# leon2_model: IP-XACT component
VLNV IcronTechnologies:IcronTechnologies:leon2_model:1.0

## Parameters
addr_width = 8
bus_width = 32

## Bus interfaces (logical=physical port)
default_map: slave AGNISYS:AGNISYS:APB:1.0, memory map leon2map
  pclk=pclk, presetn=presetn, psel=psel, penable=penable, pwrite=pwrite, pprot=pprot, pstrb=pstrb, pwdata=pwdata, paddr=paddr, pready=pready, prdata=prdata, pslverr=pslverr

## Ports
in pclk
in presetn
in psel
in penable
in pwrite
in pprot[2:0]
in pstrb[(bus_width div 8 )-1:0]
in pwdata[bus_width -1:0]
in paddr[addr_width -1:0]
out pready
out prdata[bus_width -1:0]
out pslverr
in leon2_regsleon_config_dsu_in
in leon2_regsleon_config_dsu_in_enb
in leon2_regsleon_config_sdram_ctrl_in
in leon2_regsleon_config_sdram_ctrl_in_enb
in leon2_regsleon_config_num_wp_in[2:0]
in leon2_regsleon_config_num_wp_in_enb
in leon2_regsleon_config_mac_in
in leon2_regsleon_config_mac_in_enb
in leon2_regsleon_config_nwindows_in[4:0]
in leon2_regsleon_config_nwindows_in_enb
in leon2_regsleon_config_icsz_in[2:0]
in leon2_regsleon_config_icsz_in_enb
in leon2_regsleon_config_ilsz_in[1:0]
in leon2_regsleon_config_ilsz_in_enb
in leon2_regsleon_config_dcsz_in[2:0]
in leon2_regsleon_config_dcsz_in_enb
in leon2_regsleon_config_dlsz_in[1:0]
in leon2_regsleon_config_dlsz_in_enb
in leon2_regsleon_config_div_in
in leon2_regsleon_config_div_in_enb
in leon2_regsleon_config_mul_in
in leon2_regsleon_config_mul_in_enb
in leon2_regsleon_config_ahb_stat_in
in leon2_regsleon_config_ahb_stat_in_enb
in leon2_regsleon_config_fpu_in[1:0]
in leon2_regsleon_config_fpu_in_enb
in leon2_regsleon_config_pci_core_in[1:0]
in leon2_regsleon_config_pci_core_in_enb
in leon2_regsleon_config_write_prot_in[1:0]
in leon2_regsleon_config_write_prot_in_enb
out leon2_regsmem_ctrl_mcfg{n}_enb (n=1..3)
out leon2_regsmem_ctrl_mcfg1_io_bus_width_r[31:0]
out leon2_regsmem_ctrl_mcfg1_bus_rdy_en_r
out leon2_regsmem_ctrl_mcfg1_bus_err_en_r
out leon2_regsmem_ctrl_mcfg1_io_ws_r[3:0]
out leon2_regsmem_ctrl_mcfg1_io_en_r
out leon2_regsmem_ctrl_mcfg1_prom_wr_en_r
out leon2_regsmem_ctrl_mcfg1_prom_width_r[1:0]
out leon2_regsmem_ctrl_mcfg1_prom_wr_ws_r[3:0]
out leon2_regsmem_ctrl_mcfg1_prom_rd_ws_r[3:0]
out leon2_regsmem_ctrl_mcfg2_sdram_refresh_r
out leon2_regsmem_ctrl_mcfg2_sdram_trp_r
out leon2_regsmem_ctrl_mcfg2_sdram_trfc_r[2:0]
out leon2_regsmem_ctrl_mcfg2_sdram_cas_dly_r
out leon2_regsmem_ctrl_mcfg2_sdram_bank_size_r[2:0]
out leon2_regsmem_ctrl_mcfg2_sdram_col_size_r[1:0]
out leon2_regsmem_ctrl_mcfg2_sdram_cmd_r[1:0]
out leon2_regsmem_ctrl_mcfg2_sdram_64_r
out leon2_regsmem_ctrl_mcfg2_sdram_enable_r
out leon2_regsmem_ctrl_mcfg2_sram_disable_r
out leon2_regsmem_ctrl_mcfg2_ram_bank_size_r[3:0]
out leon2_regsmem_ctrl_mcfg2_bus_rdy_en_r
out leon2_regsmem_ctrl_mcfg2_rmw_r
out leon2_regsmem_ctrl_mcfg2_ram_width_r[1:0]
out leon2_regsmem_ctrl_mcfg2_ram_wr_ws_r[1:0]
out leon2_regsmem_ctrl_mcfg2_ram_rd_ws_r[1:0]
out leon2_regsmem_ctrl_mcfg3_sdram_refresh_val_r[14:0]
out leon2_regscache_controller_cache_control_enb
out leon2_regscache_controller_cache_control_ds_r
out leon2_regscache_controller_cache_control_fd_r
out leon2_regscache_controller_cache_control_fi_r
out leon2_regscache_controller_cache_control_ib_r
out leon2_regscache_controller_cache_control_dcf_r
out leon2_regscache_controller_cache_control_icf_r
out leon2_regscache_controller_cache_control_dcs_r[1:0]
out leon2_regscache_controller_cache_control_ics_r[1:0]
out leon2_regscache_controller_power_down_enb
out leon2_regscache_controller_power_down_pd_r[31:0]
out leon2_regstimers_timer1_counter_enb
out leon2_regstimers_timer1_counter_counter_r[23:0]
out leon2_regstimers_timer1_reload_enb
out leon2_regstimers_timer1_reload_reload_r[23:0]
out leon2_regstimers_timer1_control_enb
out leon2_regstimers_timer1_control_ld_r
out leon2_regstimers_timer1_control_rl_r
out leon2_regstimers_timer1_control_en_r
out leon2_regstimers_watchdog_counter_enb
out leon2_regstimers_watchdog_counter_counter_r[23:0]
out leon2_regstimers_timer2_counter_enb
out leon2_regstimers_timer2_counter_counter_r[23:0]
out leon2_regstimers_timer2_reload_enb
out leon2_regstimers_timer2_reload_reload_r[23:0]
out leon2_regstimers_timer2_control_enb
out leon2_regstimers_timer2_control_ld_r
out leon2_regstimers_timer2_control_rl_r
out leon2_regstimers_timer2_control_en_r
out leon2_regstimers_prescaler_counter_enb
out leon2_regstimers_prescaler_counter_counter_r[9:0]
out leon2_regstimers_prescaler_reload_enb
out leon2_regstimers_prescaler_reload_reload_r[9:0]
out leon2_regsuarts_uart1_data_enb
out leon2_regsuarts_uart1_data_data_r[7:0]
out leon2_regsuarts_uart1_control_enb
out leon2_regsuarts_uart1_control_ec_r
out leon2_regsuarts_uart1_control_lb_r
out leon2_regsuarts_uart1_control_fl_r
out leon2_regsuarts_uart1_control_pe_r
out leon2_regsuarts_uart1_control_ps_r
out leon2_regsuarts_uart1_control_ti_r
out leon2_regsuarts_uart1_control_ri_r
out leon2_regsuarts_uart1_control_te_r
out leon2_regsuarts_uart1_control_re_r
out leon2_regsuarts_uart1_scaler_enb
out leon2_regsuarts_uart1_scaler_scaler_r[11:0]
out leon2_regsuarts_uart2_data_enb
out leon2_regsuarts_uart2_data_data_r[7:0]
out leon2_regsuarts_uart2_control_enb
out leon2_regsuarts_uart2_control_ec_r
out leon2_regsuarts_uart2_control_lb_r
out leon2_regsuarts_uart2_control_fl_r
out leon2_regsuarts_uart2_control_pe_r
out leon2_regsuarts_uart2_control_ps_r
out leon2_regsuarts_uart2_control_ti_r
out leon2_regsuarts_uart2_control_ri_r
out leon2_regsuarts_uart2_control_te_r
out leon2_regsuarts_uart2_control_re_r
out leon2_regsuarts_uart2_scaler_enb
out leon2_regsuarts_uart2_scaler_scaler_r[11:0]
out leon2_regsirqctrl_int_mask_enb
out leon2_regsirqctrl_int_mask_ilevel_r[14:0]
out leon2_regsirqctrl_int_mask_imask_r[14:0]
out leon2_regsirqctrl_int_clear_enb
out leon2_regsirqctrl_int_clear_iclear_r[14:0]
out leon2_regsio_port_io_val_enb
out leon2_regsio_port_io_val_ioval_r[15:0]
out leon2_regsio_port_io_dir_enb
out leon2_regsio_port_io_dir_iodir_r[17:0]
out leon2_regsio_port_io_int_cfg_enb
out leon2_regsio_port_io_int_cfg_en{n}_r (n=0..3)
out leon2_regsio_port_io_int_cfg_le{n}_r (n=0..3)
out leon2_regsio_port_io_int_cfg_pl{n}_r (n=0..3)
out leon2_regsio_port_io_int_cfg_isel{n}_r[4:0] (n=0..3)
out leon2_regsirqctrl2_int_mask_enb
out leon2_regsirqctrl2_int_mask_imask_r[31:0]
out leon2_regsirqctrl2_int_status_clear_enb
out leon2_regsirqctrl2_int_status_clear_iclear_r[25:0]
out leon2_regsirqctrl2_int_status_clear_ip_or_iclear_r
out leon2_regsirqctrl2_int_status_clear_irl_or_iclear_r[4:0]
out leon2_regsdsu_uart_dsu_control_enb
out leon2_regsdsu_uart_dsu_control_bl_r
out leon2_regsdsu_uart_dsu_control_en_r
out leon2_regsdsu_uart_dsu_scaler_enb
out leon2_regsdsu_uart_dsu_scaler_scaler_r[13:0]

## Address spaces and blocks
leon2map.leon2: base 0x000, range 0x100, width 32

## Registers
Registers are 32-bit, read-write, reset 0x0 unless marked. A register's access mark holds for its fields unless they carry their own. Offsets are from the block's base; lines under a group give offsets from that group; [hi:lo] are bit positions; {n}, {i} and the like mark numbered series; 'fields as' and 'values as' point back to an identical list; <NAME> marks a mode.

## leon2map.leon2 — LEON2 Registers
Base 0x00000000
0x00 mem_ctrl group — Memory controller
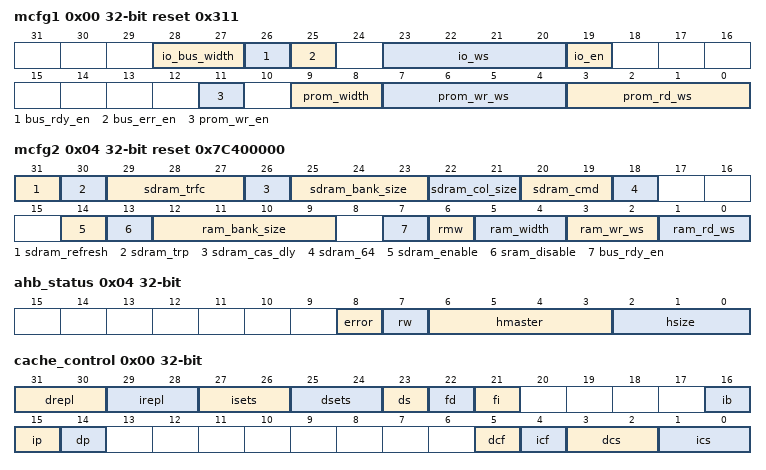
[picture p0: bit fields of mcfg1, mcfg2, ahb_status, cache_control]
  0x00 mcfg1 reset 0x311 — Memory configuration register 1
    [28:27] io_bus_width — I/O bus width. Defines the data width of the I/O area. 2'b00 : 8 2'b01 : 16 2'b10 : 32 2'b11 : Reserved
    [26] bus_rdy_en — Bus ready (BRDYN) enable.
    [25] bus_err_en — Bus error (BEXCN) enable.
    [23:20] io_ws — I/O wait states. Defines the number of wait states during I/O accesses. 4'b0000 : 0 4'b0001 : 1 . 4'b1111: 15
    [19] io_en — I/O enable. If set, access to the memory bus I/O area is enabled.
    [11] prom_wr_en — PROM write enable. If set, enables write cycles to the PROM area.
    [9:8] prom_width — PROM width. Defines the data width of the PROM area. 2'b00 : 8 2'b01 : 16 2'b10 : 32 2'b11 : Reserved
    [7:4] prom_wr_ws — PROM write wait states. Defines the number of wait states during PROM write cycles. 4'b0000 : 0 4'b0001 : 1 . 4'b1111: 15
    [3:0] prom_rd_ws — PROM read wait states. Defines the number of wait states during PROM read cycles. 4'b0000 : 0 4'b0001 : 1 . 4'b1111: 15
  0x04 mcfg2 reset 0x7C400000 — Memory configuration register 2
    [31] sdram_refresh — SDRAM refresh. If set, the SDRAM refresh will be enabled.
    [30] sdram_trp — SDRAM tRP timing. tRP will be equal to 2 or 3 system clocks (0/1).
    [29:27] sdram_trfc — SDRAM tRFC timing. tRFC will be equal to 3 + field-value system clocks.
    [26] sdram_cas_dly — SDRAM CAS delay. Selects 2 or 3 cycle CAS delay (0/1). When changed, a LOAD-COMMAND-REGISTER command must be issued at the same time. Also sets RAS/CAS delay (tRCD).
    [25:23] sdram_bank_size — SDRAM banks size. Defines the banks size for SDRAM chip selects. 3'b000 : 4 Mbyte 3'b001 : 8 Mbyte . 3'b111 : 512 Mbyte
    [22:21] sdram_col_size — SDRAM column size. 2'b00 : 256 2'b01 : 512 2'b10 : 1024 2'b11 : 2048 - when [25:23] != 3'b111 2'b11 : 4096 - when [25:23] == 3'b111
    [20:19] sdram_cmd — SDRAM command. Writing non-zero value will generate an SDRAM command. The field is reset after command has been executed. 2'b00 : Reserved 2'b01 : PRECHARGE 2'b10 : AUTO-REFRESH 2'b11 : LOAD-COMMAND-REGISTER
    [18] sdram_64 — 64-bit SDRAM. If set, the SDRAM controller is configured to use 64-bit wide SDRAM.
    [14] sdram_enable — SDRAM enable. If set, the SDRAM controller will be enabled.
    [13] sram_disable — SRAM disable. If set together with bit 14 (SDRAM enable), the static RAM access will be disabled.
    [12:9] ram_bank_size — RAM bank size. Defines the size of each RAM bank. 4'b0000 : 8 Kbyte 4'b0001 : 16 Kbyte . 4'b1111 : 256 Mbyte
    [7] bus_rdy_en — Bus ready enable. If set, will enable BRDYN for RAM area.
    [6] rmw — Read-Modify-Write. Enable read-modify-write cycles on sub-word writes to 16- and 32-bit areas with common write strobe (no byte write strobe).
    [5:4] ram_width — RAM width. Defines the data width of the RAM area. 2'b00 : 8 2'b01 : 16 2'b10 : 32 2'b11 : Reserved
    [3:2] ram_wr_ws — RAM write wait states. Defines the number of wait statesduring RAM write cycles. 2'b00 : 0 2'b01 : 1 2'b10 : 2 2'b11 : 3
    [1:0] ram_rd_ws — RAM read wait states. Defines the number of wait states during RAM read cycles. 2'b00 : 0 2'b01 : 1 2'b10 : 2 2'b11 : 3
  0x08 mcfg3 — Memory configuration register 3
    [26:12] sdram_refresh_val — Reload value for the SDRAM refresh counter.
0x0C ahb_stat group — AHB Status
  0x00 ahb_failing — AHB failing address
    [31:0] ahb_failing — AHB failing register. The address of the transaction that caused an AHB error response.
  0x04 ahb_status
    [8] error — Error. This bit is set when an error occurred. Write a 1 to clear this field.
    [7] rw — RW - Read/Write. This bit is set if the failed access was a read cycle, otherwise it is cleared.
    [6:3] hmaster — HMASTER - AHB master. This field contains the HMASTER[3:0] of the failed access.
    [2:0] hsize — HSIZE - transfer size. This field contains the HSIZE[2:0] of the failed transfer.
0x14 cache_controller group
  0x00 cache_control access per field — Cache control register (CRR)
    [31:30] drepl ro — Data cache replacement policy (DREPL): 2'b00 : no replacement policy (direct-mapped cache) 2'b01 : random 2'b10 : least-recently-replaced (LRR) 2'b11 : least-recenty-used (LRU)
    [29:28] irepl ro — Instruction cache replacement policy (IREPL): 2'b00 : no replacement policy (direct-mapped cache) 2'b01 : random 2'b10 : least-recently-replaced (LRR) 2'b11 : least-recenty-used (LRU)
    [27:26] isets ro — Instruction cache associativity (ISETS) - Number of sets in the instruction cache: 2'b00 : direct mapped 2'b01 : 2-way associative 2'b10 : 3-way associative 2'b11 : 4-way associative
    [25:24] dsets ro — Data cache associativity (DSETS) - Number of sets in the data cache: 2'b00 : direct mapped 2'b01 : 2-way associative 2'b10 : 3-way associative 2'b11 : 4-way associative
    [23] ds rw — Data cache snoop enable (DS) - If set, will enable data cache snooping.
    [22] fd wo — Flush Data cache (FD) - If set, will flush the data cache. Always reads as zero.
    [21] fi wo — Flush Instruction cache (FI) - If set, will flush the instruction cache. Always reads as zero.
    [16] ib rw — Instruction burst fetch (IB) - This bit enables burst fill during instruction fetch.
    [15] ip ro — Instruction cache flush pending (IP) - This bit is set when an instruction cache flush operation is in progress.
    [14] dp ro — Data cache flush pending (DP) - This bit is set when a data cache flush operation is in progress.
    [5] dcf rw — Data Cache Freeze on Interrupt (DCF) - If set, the data cache will automatically be frozen when an asynchronous interrupt is taken.
    [4] icf rw — Instruction Cache Freeze on Interrupt (ICF) - If set, the instruction cache will automatically be frozen when an asynchronous interrupt is taken.
    [3:2] dcs rw — Data Cache State (DCS) - Indicates the current data cache state according to the following: 2'b00 : Disabled 2'b01 : Frozen 2'b10 : Disabled 2'b11 : Enabled
    [1:0] ics rw — Instruction Cache State (ICS) - Indicates the current instruction cache state according to the following: 2'b00 : Disabled 2'b01 : Frozen 2'b10 : Disabled 2'b11 : Enabled
  0x04 power_down wo
    [31:0] pd — The processor can be powered-down by writing an arbitrary value to the power-down register. Power-down mode will be entered on the next load or store instruction. To enter power-down mode immediately, a store to the power-down register should be performed followed by a dummy load.
0x1C write_prot group — Write Protection
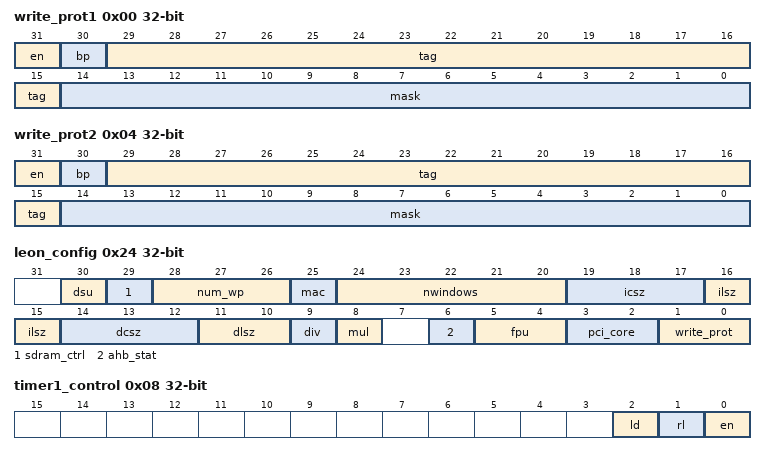
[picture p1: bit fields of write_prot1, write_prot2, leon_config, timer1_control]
  0x00 write_prot1 ro — Write protection register 1
    [31] en — Enable (EN) - If set, enables the write protect unit
    [30] bp — Block Protect (BP) - If set, selects block protect mode
    [29:15] tag — Address tag (TAG) - This field is compared against address (29:15)
    [14:0] mask — Address mask (MASK) - This field contains the address mask
  0x04 write_prot2 ro — Write protection register 2
    fields as write_prot.write_prot1
0x24 leon_config ro — LEON configuration register
  [30] dsu — Debug support unit present 1'b0 : disabled 1'b1 : present
  [29] sdram_ctrl — SDRAM controller present 1'b0 : disabled 1'b1 : present
  [28:26] num_wp — Number of implemented watchpoints (0 - 4)
  [25] mac — UMAC/SMAC instruction implemented
  [24:20] nwindows — Number of register windows. The implemented number of SPARC register windows - 1.
  [19:17] icsz — Instruction cache size. The size (in Kbytes) of the instruction cache. Cache size = 2^icsz.
  [16:15] ilsz — Instruction cache line size. The line size (in 32-bit words) of each line. Line size = 2^ilsz.
  [14:12] dcsz — Data cache size. The size (in Kbytes) of the data cache. Cache size = 2^dcsz.
  [11:10] dlsz — Data cache line size. The line size (in 32-bit words) of each line. Line size = 2^dlsz.
  [9] div — UDIV/SDIV instruction implemented
  [8] mul — UMUL/SMUL instruction implemented
  [6] ahb_stat — Memory status and failing address register present
  [5:4] fpu — FPU type 2'b00 : none 2'b01 : Meiko
  [3:2] pci_core — PCI core type 2'b00 : none 2'b01 : InSilicon 2'b10 : ESA 2'b11 : Other
  [1:0] write_prot — Write protection type 2'b00 : none 2'b01 : standard
0x40 timers group
  0x00 timer1_counter
    [23:0] counter — Timer 1 counter value
  0x04 timer1_reload
    [23:0] reload — Timer 1 reload value
  0x08 timer1_control
    [2] ld — Load counter (LD) - When written with 1, will load the timer reload register into the timer counter register. Always reads as a 0.
    [1] rl — Reload counter (RL) - If RL is set, then the counter will automatically be reloaded with the reload value after each underflow.
    [0] en — Enable (EN) - Enables the timer when set.
  0x0C watchdog_counter
    [23:0] counter — Watchdog counter value
  0x10 timer2_counter
    [23:0] counter — Timer 2 counter value
  0x14 timer2_reload
    [23:0] reload — Timer 2 reload value
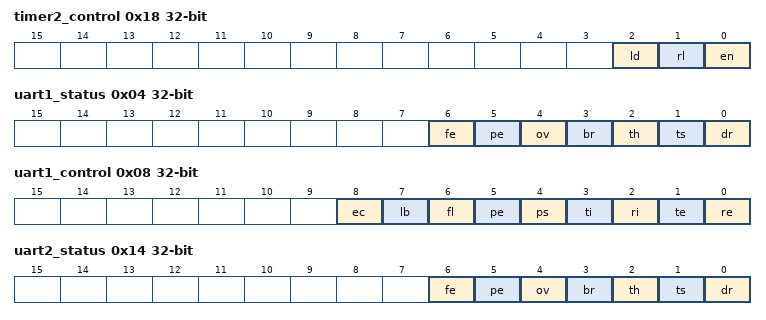
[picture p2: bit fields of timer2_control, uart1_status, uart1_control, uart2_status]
  0x18 timer2_control
    fields as timers.timer1_control
  0x20 prescaler_counter
    [9:0] counter — Prescaler counter value
  0x24 prescaler_reload
    [9:0] reload — Prescaler reload value
0x70 uarts group
  0x00 uart1_data
    [7:0] data — Holding register for both read and write access
  0x04 uart1_status ro
    [6] fe — Framing error (FE) - Indicates that a framing error was detected.
    [5] pe — Parity error (PE) - Indicates that a parity error was detected.
    [4] ov — Overrun (OV) - Indicates that one or more characters have been lost due to overrun.
    [3] br — Break received (BR) - Indicates that a BREAK has been received.
    [2] th — Transmitter hold register empty (TH) - Indicates that the transmitter hold register is empty.
    [1] ts — Transmitter shift register empty (TS) - Indicates that the transmitter shift register is empty.
    [0] dr — Data ready (DR) - Indicates that new data is available in the receiver holding register.
  0x08 uart1_control
    [8] ec — External clock (EC) - If set, the UART scaler will be clocked by PIO[3].
    [7] lb — Loop back (LB) - If set, loop back mode will be enabled.
    [6] fl — Flow control (FL) - If set, enables flow control using CTS/RTS.
    [5] pe — Parity enable (PE) - If set, enables parity generation and checking.
    [4] ps — Parity select (PS) - Selects parity polarity. 1'b0 : even parity 1'b1 : odd parity
    [3] ti — Transmitter interrupt enable (RI) - If set, enables generation of transmitter interrupt.
    [2] ri — Receiver interrupt enable (RI) - If set, enables generation of receiver interrupt.
    [1] te — Transmitter enable (TE) - If set, enables the transmitter.
    [0] re — Receiver enable (RE) - If set, enables the receiver.
  0x0C uart1_scaler
    [11:0] scaler — UART1 scaler reload value
  0x10 uart2_data
    [7:0] data — Holding register for both read and write access
  0x14 uart2_status ro
    fields as uarts.uart1_status
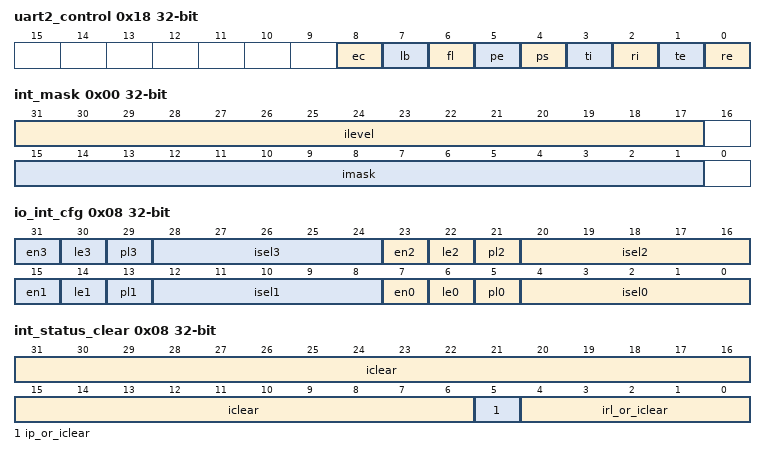
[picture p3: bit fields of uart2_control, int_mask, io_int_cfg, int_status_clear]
  0x18 uart2_control
    fields as uarts.uart1_control
  0x1C uart2_scaler
    [11:0] scaler — UART2 scaler reload value
0x90 irqctrl group — Interrupt controller
  0x00 int_mask — Interrupt mask register
    [31:17] ilevel — Interrupt level (ILEVEL[15:1]) - Indicates whether an interrupt belongs to priority level 1 (ILEVEL[n]=1 or level 0 (ILEVEL[n]=0).
    [15:1] imask — Interrupt mask (IMASK[15:1]) - Indicates whether an interrupt is masked (IMASK[n]=0 or enabled (IMASK[n]=1).
  0x04 int_pending ro — Interrupt pending register
    [15:1] ipend — Interrupt pending (IPEND[15:1]) - Indicates whether an interrupt is pending (IPEND[n]=1).
  0x08 int_force ro — Interrupt force register
    [15:1] iforce — Interrupt force (IFORCE[15:1]) - Indicates whether an interrupt is being forced (IFORCE[n]=1).
  0x0C int_clear — Interrupt clear register
    [15:1] iclear — Interrupt clear (ICLEAR[15:1]) - If written with a 1, will clear the corresponding bit(s) in the interrupt pending register. A read returns 0.
0xA0 io_port group
  0x00 io_val — I/O port input/output register
    [15:0] ioval — IOVALn - I/O port value. On a read the I/O ports that are configured as inputs return their current value. When written, the value will be driven onto the I/O ports that are configured as outputs.
  0x04 io_dir — I/O port direction register
    [17:0] iodir — IODIRn - I/O port direction. The value of IODIR[15:0] defines the direction of I/O ports 15 - 0 (PIO[15:0]). If bit n is set the corresponding I/O port becomes an output, otherwise it is an input. IODIR[16] controls D[15:8] while IODIR[17] controls D[7:0].
  0x08 io_int_cfg — I/O port interrupt config register
    [8n+7] en{n} (n=0..3) — EN{n} - Enable. If set, the corresponding interrupt will be enabled, otherwise it will be masked.
    [8n+6] le{n} (n=0..3) — LE{n} - Level/edge triggered. If set, the interrupt will be edge-triggered, otherwise level sensitive.
    [8n+5] pl{n} (n=0..3) — PL{n} - Polarity. If set, the corresponding interrupt will be active high (or edge-triggered on positive edge). Otherwise, it will be active low (or edge-triggered on negative edge).
    [8n+4:8n] isel{n} (n=0..3) — ISEL{n} - I/O port select. The value of this field defines which I/O port (0 - 31) should generate parallel I/O port interrupt {n}.
0xB0 irqctrl2 group — Secondary interrupt controller
  0x00 int_mask — Secondary interrupt mask register
    [31:0] imask — Interrupt mask - Indicates whether an interrupt is masked (IMASK[n]=0 or enabled (IMASK[n]=1).
  0x04 int_pending ro — Secondary interrupt pending register
    [31:0] ipend — Interrupt pending - Indicates whether an interrupt is pending (IPEND[n]=1).
  0x08 int_status_clear — Secondary interrupt status and clear register
    [31:6] iclear — Interrupt clear - If written with a 1, will clear the corresponding bit(s) in the interrupt pending register. A read returns 0.
    [5] ip_or_iclear — Interrupt pending - If set, then IRL is valid. If cleared, no unmasked interrupt is pending. When written, clears pending secondary interrupt 5.
    [4:0] irl_or_iclear — Interrupt request level - Indicates the highest unmasked pending interrupt. When written, clears the pending secondary interrupts (4:0) that have their bit set to 1.
0xC4 dsu_uart group
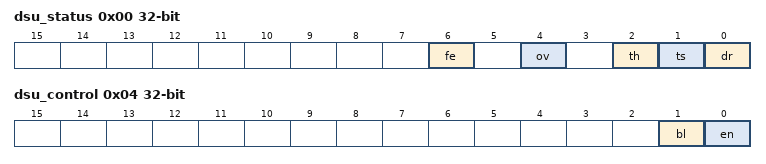
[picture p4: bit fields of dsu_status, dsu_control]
  0x00 dsu_status ro
    [6] fe — Framing error (FE) - Indicates that a framing error was detected.
    [4] ov — Overrun (OV) - Indicates that one or more characters have been lost due to overrun.
    [2] th — Transmitter hold register empty (TH) - Indicates that the transmitter hold register is empty.
    [1] ts — Transmitter shift register empty (TS) - Indicates that the transmitter shift register is empty.
    [0] dr — Data ready (DR) - Indicates that new data has been received and not yet read-out by the AHB master interface.
  0x04 dsu_control
    [1] bl — Baud rate locked (BL) - Is automatically set when the baud rate is locked.
    [0] en — Receiver enable (RE) - If set, enables both the transmitter and receiver.
  0x08 dsu_scaler
    [13:0] scaler — Scaler reload value = (((system_clk_in_hz*10)/(baudrate*8))-5)/10
